VERSION ""

NS_ :

BS_:

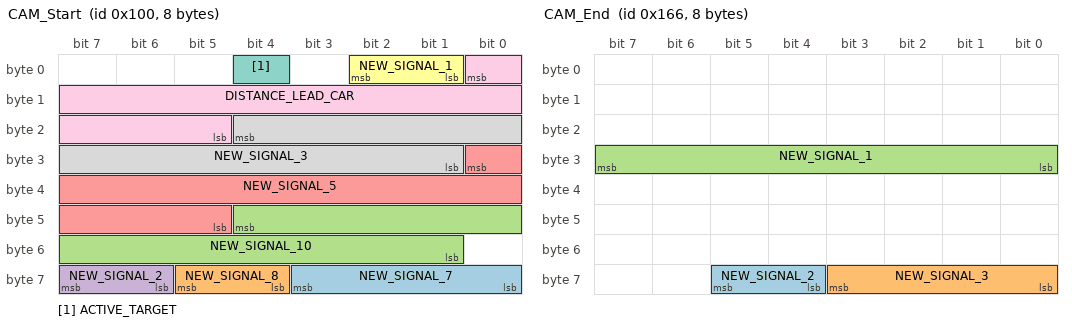
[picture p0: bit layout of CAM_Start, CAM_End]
BO_ 256 CAM_Start: 8 XXX
 SG_ NEW_SIGNAL_7 : 56|4@1+ (1,0) [0|15] "" XXX
 SG_ NEW_SIGNAL_8 : 61|2@0+ (1,0) [0|15] "" XXX
 SG_ NEW_SIGNAL_10 : 44|12@0+ (1,0) [0|15] "" XXX
 SG_ NEW_SIGNAL_2 : 63|2@0+ (1,0) [0|3] "" XXX
 SG_ NEW_SIGNAL_5 : 24|12@0+ (1,0) [0|255] "" XXX
 SG_ NEW_SIGNAL_1 : 2|2@0+ (1,0) [0|1] "" XXX
 SG_ ACTIVE_TARGET : 4|1@0+ (1,0) [0|1] "" XXX
 SG_ NEW_SIGNAL_3 : 20|12@0+ (1,0) [0|7] "" XXX
 SG_ DISTANCE_LEAD_CAR : 0|12@0+ (1,0) [0|255] "" XXX

BO_ 358 CAM_End: 8 XXX
 SG_ NEW_SIGNAL_2 : 61|2@0+ (1,0) [0|3] "" XXX
 SG_ NEW_SIGNAL_3 : 59|4@0+ (1,0) [0|15] "" XXX
 SG_ NEW_SIGNAL_1 : 31|8@0+ (1,0) [0|255] "" XXX

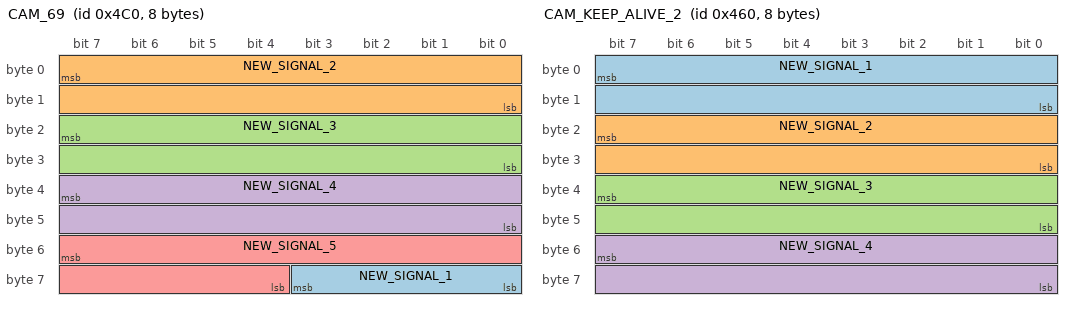
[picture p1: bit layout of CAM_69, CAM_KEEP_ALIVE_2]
BO_ 1216 CAM_69: 8 XXX
 SG_ NEW_SIGNAL_1 : 56|4@1+ (1,0) [0|15] "" XXX
 SG_ NEW_SIGNAL_2 : 7|16@0+ (1,0) [0|65535] "" XXX
 SG_ NEW_SIGNAL_3 : 23|16@0+ (1,0) [0|65535] "" XXX
 SG_ NEW_SIGNAL_4 : 39|16@0+ (1,0) [0|65535] "" XXX
 SG_ NEW_SIGNAL_5 : 55|12@0+ (1,0) [0|7] "" XXX

BO_ 1120 CAM_KEEP_ALIVE_2: 8 XXX
 SG_ NEW_SIGNAL_1 : 7|16@0+ (1,0) [0|65535] "" XXX
 SG_ NEW_SIGNAL_2 : 23|16@0+ (1,0) [0|65535] "" XXX
 SG_ NEW_SIGNAL_3 : 39|16@0+ (1,0) [0|65535] "" XXX
 SG_ NEW_SIGNAL_4 : 55|16@0+ (1,0) [0|65535] "" XXX

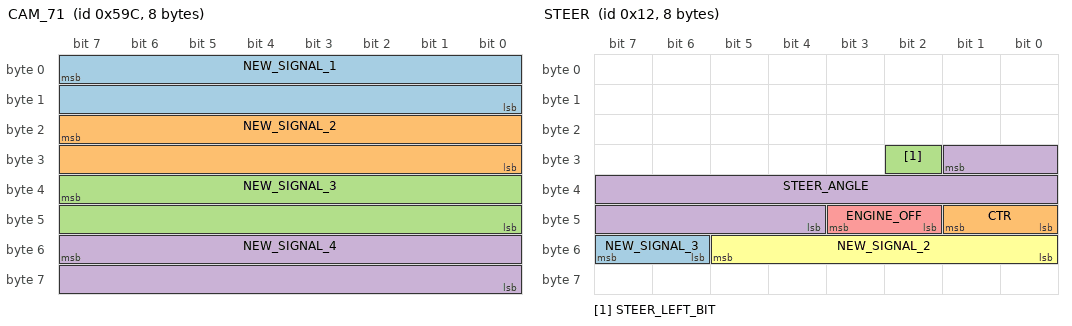
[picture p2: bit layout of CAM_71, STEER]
BO_ 1436 CAM_71: 8 XXX
 SG_ NEW_SIGNAL_1 : 7|16@0+ (1,0) [0|255] "" XXX
 SG_ NEW_SIGNAL_2 : 23|16@0+ (1,0) [0|65535] "" XXX
 SG_ NEW_SIGNAL_3 : 39|16@0+ (1,0) [0|65535] "" XXX
 SG_ NEW_SIGNAL_4 : 55|16@0+ (1,0) [0|65535] "" XXX

BO_ 18 STEER: 8 XXX
 SG_ NEW_SIGNAL_3 : 55|2@0+ (1,0) [0|15] "" XXX
 SG_ CTR : 41|2@0+ (1,0) [0|3] "" XXX
 SG_ STEER_LEFT_BIT : 26|1@0+ (1,0) [0|1] "" XXX
 SG_ STEER_ANGLE : 25|14@0- (1,375) [0|65536] "" XXX
 SG_ ENGINE_OFF : 43|2@0+ (1,0) [0|63] "" XXX
 SG_ NEW_SIGNAL_2 : 53|6@0+ (1,0) [0|15] "" XXX

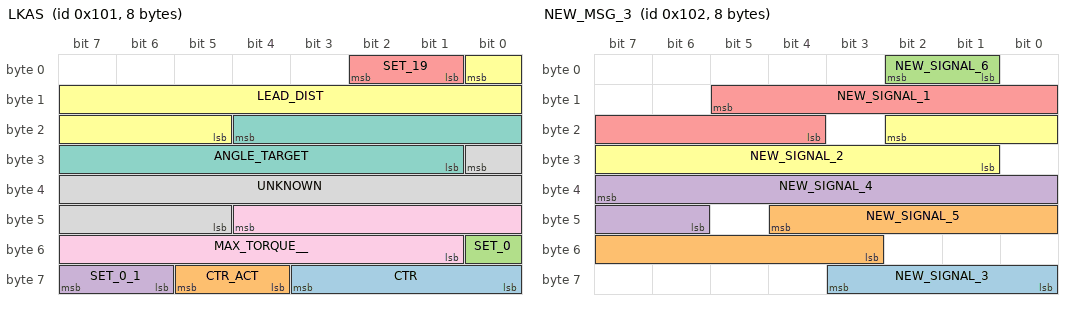
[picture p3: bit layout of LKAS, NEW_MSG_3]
BO_ 257 LKAS: 8 XXX
 SG_ CTR : 59|4@0+ (1,0) [0|255] "" XXX
 SG_ CTR_ACT : 61|2@0+ (1,0) [0|3] "" XXX
 SG_ SET_0 : 48|1@1+ (1,0) [0|3] "" XXX
 SG_ SET_0_1 : 63|2@0+ (1,0) [0|3] "" XXX
 SG_ SET_19 : 2|2@0+ (1,0) [0|255] "" XXX
 SG_ LEAD_DIST : 0|12@0+ (1,0) [0|255] "" XXX
 SG_ ANGLE_TARGET : 20|12@0+ (1,0) [0|4095] "" XXX
 SG_ UNKNOWN : 24|12@0+ (1,0) [0|4095] "" XXX
 SG_ MAX_TORQUE__ : 44|12@0- (1,0) [0|4095] "" XXX

BO_ 258 NEW_MSG_3: 8 XXX
 SG_ NEW_SIGNAL_3 : 59|4@0+ (1,0) [0|255] "" XXX
 SG_ NEW_SIGNAL_5 : 44|10@0- (1,0) [0|1] "" XXX
 SG_ NEW_SIGNAL_6 : 1|2@1+ (1,0) [0|3] "" XXX
 SG_ NEW_SIGNAL_4 : 39|10@0- (1,0) [0|1] "" XXX
 SG_ NEW_SIGNAL_1 : 13|10@0- (1,0) [0|255] "" XXX
 SG_ NEW_SIGNAL_2 : 18|10@0- (1,0) [0|255] "" XXX

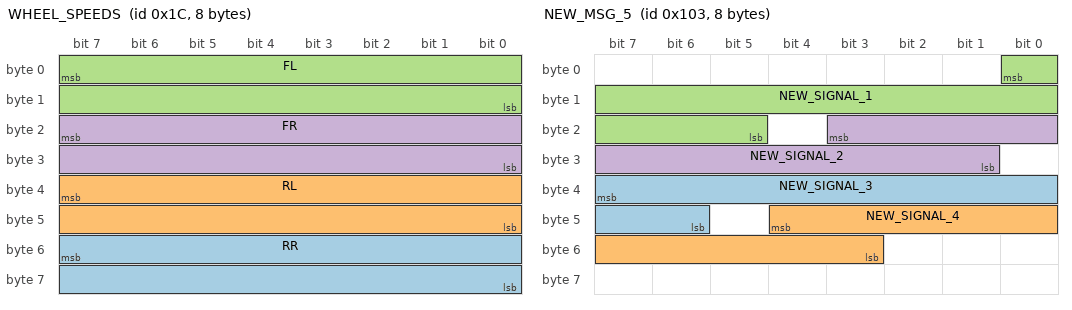
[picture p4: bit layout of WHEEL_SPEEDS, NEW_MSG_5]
BO_ 28 WHEEL_SPEEDS: 8 XXX
 SG_ RR : 55|16@0+ (0.01,-100) [0|65535] "" XXX
 SG_ RL : 39|16@0+ (0.01,-102) [0|65535] "" XXX
 SG_ FL : 7|16@0+ (0.01,-100) [0|65535] "" XXX
 SG_ FR : 23|16@0+ (0.01,-100) [0|65535] "" XXX

BO_ 259 NEW_MSG_5: 8 XXX
 SG_ NEW_SIGNAL_3 : 39|10@0- (1,0) [0|1] "" XXX
 SG_ NEW_SIGNAL_4 : 44|10@0- (1,0) [0|1] "" XXX
 SG_ NEW_SIGNAL_1 : 0|12@0- (1,0) [0|255] "" XXX
 SG_ NEW_SIGNAL_2 : 19|11@0- (1,0) [0|10000000] "" XXX

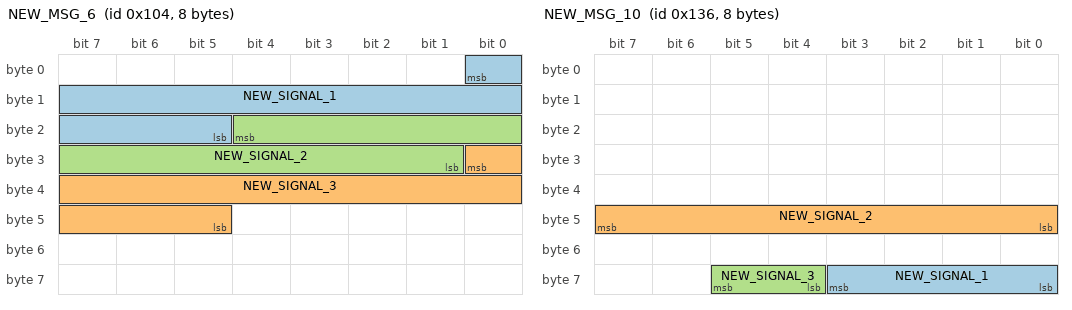
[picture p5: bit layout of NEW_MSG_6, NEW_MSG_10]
BO_ 260 NEW_MSG_6: 8 XXX
 SG_ NEW_SIGNAL_1 : 0|12@0+ (1,0) [0|255] "" XXX
 SG_ NEW_SIGNAL_3 : 24|12@0+ (1,0) [0|1] "" XXX
 SG_ NEW_SIGNAL_2 : 20|12@0- (1,0) [0|1] "" XXX

BO_ 261 NEW_MSG_7: 8 XXX
 SG_ NEW_SIGNAL_1 : 15|8@0+ (1,0) [0|255] "" XXX

BO_ 262 NEW_MSG_8: 8 XXX
 SG_ NEW_SIGNAL_1 : 15|8@0- (1,0) [0|255] "" XXX
 SG_ NEW_SIGNAL_2 : 7|8@0+ (1,0) [0|255] "" XXX

BO_ 263 NEW_MSG_9: 8 XXX
 SG_ NEW_SIGNAL_1 : 15|8@0+ (1,0) [0|255] "" XXX

BO_ 310 NEW_MSG_10: 8 XXX
 SG_ NEW_SIGNAL_1 : 56|4@1+ (1,0) [0|255] "" XXX
 SG_ NEW_SIGNAL_2 : 47|8@0+ (1,0) [0|255] "" XXX
 SG_ NEW_SIGNAL_3 : 61|2@0+ (1,0) [0|3] "" XXX

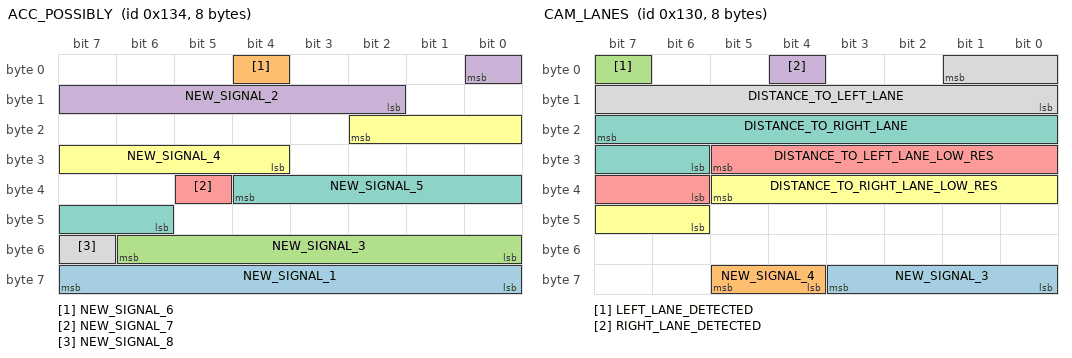
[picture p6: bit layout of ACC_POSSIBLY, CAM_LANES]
BO_ 308 ACC_POSSIBLY: 8 XXX
 SG_ NEW_SIGNAL_1 : 63|8@0+ (1,0) [0|255] "" XXX
 SG_ NEW_SIGNAL_6 : 4|1@0+ (1,0) [0|255] "" XXX
 SG_ NEW_SIGNAL_3 : 54|7@0+ (1,0) [0|15] "" XXX
 SG_ NEW_SIGNAL_2 : 0|7@0+ (1,0) [0|63] "" XXX
 SG_ NEW_SIGNAL_7 : 37|1@0+ (1,0) [0|1] "" XXX
 SG_ NEW_SIGNAL_4 : 18|7@0+ (1,0) [0|15] "" XXX
 SG_ NEW_SIGNAL_5 : 36|7@0+ (1,0) [0|1] "" XXX
 SG_ NEW_SIGNAL_8 : 55|1@0+ (1,0) [0|1] "" XXX

BO_ 304 CAM_LANES: 8 XXX
 SG_ NEW_SIGNAL_3 : 59|4@0+ (1,0) [0|255] "" XXX
 SG_ NEW_SIGNAL_4 : 61|2@0+ (1,0) [0|3] "" XXX
 SG_ LEFT_LANE_DETECTED : 7|1@0+ (1,0) [0|1] "" XXX
 SG_ RIGHT_LANE_DETECTED : 4|1@0+ (1,0) [0|255] "" XXX
 SG_ DISTANCE_TO_LEFT_LANE_LOW_RES : 29|8@0+ (1,0) [0|4095] "" XXX
 SG_ DISTANCE_TO_RIGHT_LANE_LOW_RES : 37|8@0+ (1,0) [0|15] "" XXX
 SG_ DISTANCE_TO_RIGHT_LANE : 23|10@0- (1,0) [0|2047] "" XXX
 SG_ DISTANCE_TO_LEFT_LANE : 1|10@0- (1,0) [0|1] "" XXX

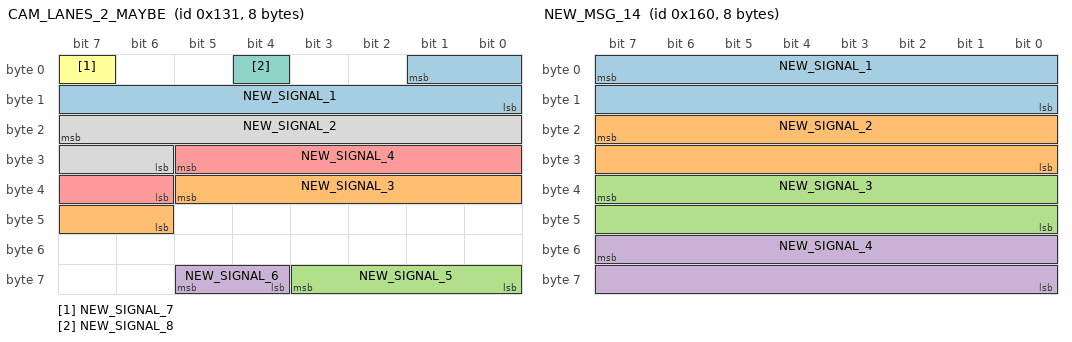
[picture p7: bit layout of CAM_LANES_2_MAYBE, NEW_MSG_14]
BO_ 305 CAM_LANES_2_MAYBE: 8 XXX
 SG_ NEW_SIGNAL_1 : 1|10@0+ (1,0) [0|255] "" XXX
 SG_ NEW_SIGNAL_3 : 37|8@0+ (1,0) [0|15] "" XXX
 SG_ NEW_SIGNAL_5 : 56|4@1+ (1,0) [0|15] "" XXX
 SG_ NEW_SIGNAL_6 : 61|2@0+ (1,0) [0|3] "" XXX
 SG_ NEW_SIGNAL_4 : 29|8@0+ (1,0) [0|1] "" XXX
 SG_ NEW_SIGNAL_7 : 7|1@0+ (1,0) [0|1] "" XXX
 SG_ NEW_SIGNAL_8 : 4|1@0+ (1,0) [0|1] "" XXX
 SG_ NEW_SIGNAL_2 : 23|10@0+ (1,0) [0|4095] "" XXX

BO_ 352 NEW_MSG_14: 8 XXX
 SG_ NEW_SIGNAL_1 : 7|16@0+ (1,0) [0|255] "" XXX
 SG_ NEW_SIGNAL_2 : 23|16@0+ (1,0) [0|65535] "" XXX
 SG_ NEW_SIGNAL_3 : 39|16@0+ (1,0) [0|65535] "" XXX
 SG_ NEW_SIGNAL_4 : 55|16@0+ (1,0) [0|65535] "" XXX

BO_ 355 NEW_MSG_15: 8 XXX
 SG_ NEW_SIGNAL_1 : 7|8@0+ (1,0) [0|127] "" XXX

BO_ 356 NEW_MSG_16: 8 XXX
 SG_ NEW_SIGNAL_1 : 56|4@1+ (1,0) [0|15] "" XXX
 SG_ NEW_SIGNAL_2 : 61|2@0+ (1,0) [0|3] "" XXX

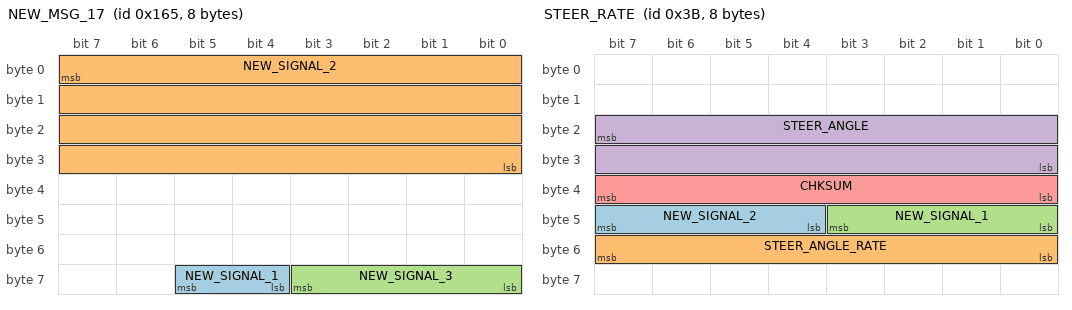
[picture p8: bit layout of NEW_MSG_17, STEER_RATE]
BO_ 357 NEW_MSG_17: 8 XXX
 SG_ NEW_SIGNAL_1 : 61|2@0+ (1,0) [0|3] "" XXX
 SG_ NEW_SIGNAL_2 : 7|32@0+ (1,0) [0|4294967295] "" XXX
 SG_ NEW_SIGNAL_3 : 56|4@1+ (1,0) [0|15] "" XXX

BO_ 59 STEER_RATE: 8 XXX
 SG_ NEW_SIGNAL_2 : 47|4@0+ (1,0) [0|15] "" XXX
 SG_ STEER_ANGLE_RATE : 55|8@0+ (0.05,0) [0|65535] "" XXX
 SG_ NEW_SIGNAL_1 : 43|4@0+ (1,0) [0|15] "" XXX
 SG_ STEER_ANGLE : 23|16@0+ (0.05,-1600) [-500|500] "" XXX
 SG_ CHKSUM : 39|8@0+ (1,0) [0|15] "" XXX

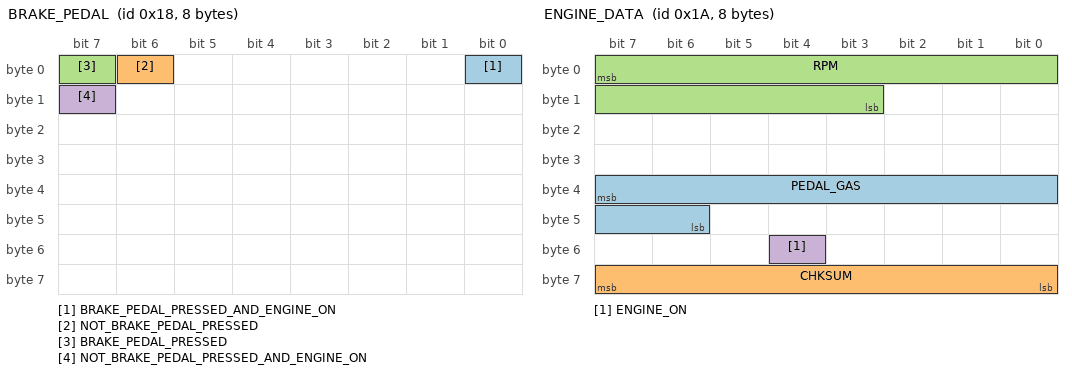
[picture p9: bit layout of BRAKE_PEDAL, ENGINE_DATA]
BO_ 24 BRAKE_PEDAL: 8 XXX
 SG_ BRAKE_PEDAL_PRESSED_AND_ENGINE_ON : 0|1@0+ (1,0) [0|3] "" XXX
 SG_ NOT_BRAKE_PEDAL_PRESSED : 6|1@0+ (1,0) [0|3] "" XXX
 SG_ BRAKE_PEDAL_PRESSED : 7|1@0+ (1,0) [0|65535] "" XXX
 SG_ NOT_BRAKE_PEDAL_PRESSED_AND_ENGINE_ON : 15|1@0+ (1,0) [0|7] "" XXX

BO_ 26 ENGINE_DATA: 8 XXX
 SG_ PEDAL_GAS : 39|10@0+ (1,0) [0|15] "" XXX
 SG_ CHKSUM : 63|8@0- (1,0) [0|15] "" XXX
 SG_ RPM : 7|13@0+ (1,0) [0|15] "" XXX
 SG_ ENGINE_ON : 52|1@0+ (1,0) [0|15] "" XXX

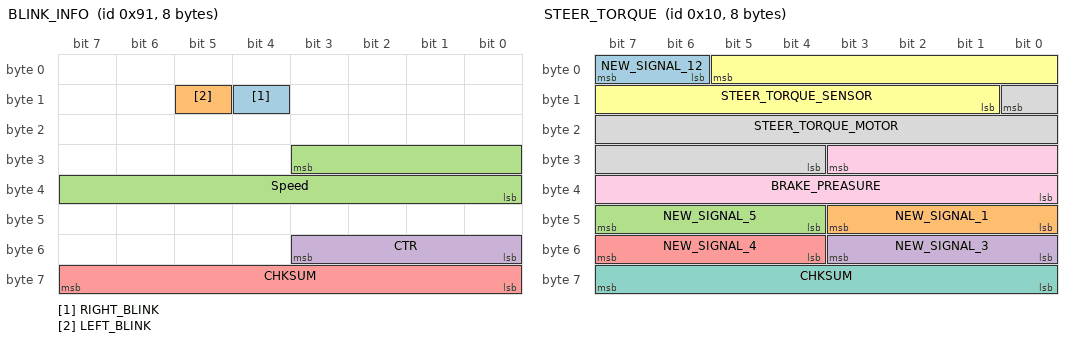
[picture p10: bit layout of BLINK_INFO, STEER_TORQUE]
BO_ 145 BLINK_INFO: 8 XXX
 SG_ RIGHT_BLINK : 12|1@0+ (1,0) [0|3] "" XXX
 SG_ LEFT_BLINK : 13|1@0+ (1,0) [0|3] "" XXX
 SG_ Speed : 27|12@0+ (1,0) [0|255] "" XXX
 SG_ CTR : 51|4@0+ (1,0) [0|15] "" XXX
 SG_ CHKSUM : 63|8@0+ (1,0) [0|15] "" XXX

BO_ 16 STEER_TORQUE: 8 XXX
 SG_ NEW_SIGNAL_12 : 7|2@0+ (1,0) [0|15] "" XXX
 SG_ NEW_SIGNAL_1 : 43|4@0+ (1,0) [0|15] "" XXX
 SG_ NEW_SIGNAL_5 : 47|4@0+ (1,0) [0|15] "" XXX
 SG_ NEW_SIGNAL_3 : 51|4@0+ (1,0) [0|15] "" XXX
 SG_ NEW_SIGNAL_4 : 55|4@0+ (1,0) [0|15] "" XXX
 SG_ STEER_TORQUE_SENSOR : 5|13@0+ (1,-4000) [0|15] "" XXX
 SG_ CHKSUM : 63|8@0- (1,0) [0|15] "" XXX
 SG_ STEER_TORQUE_MOTOR : 8|13@0+ (0.05,-205) [0|15] "" XXX
 SG_ BRAKE_PREASURE : 27|12@0+ (1,0) [0|15] "" XXX

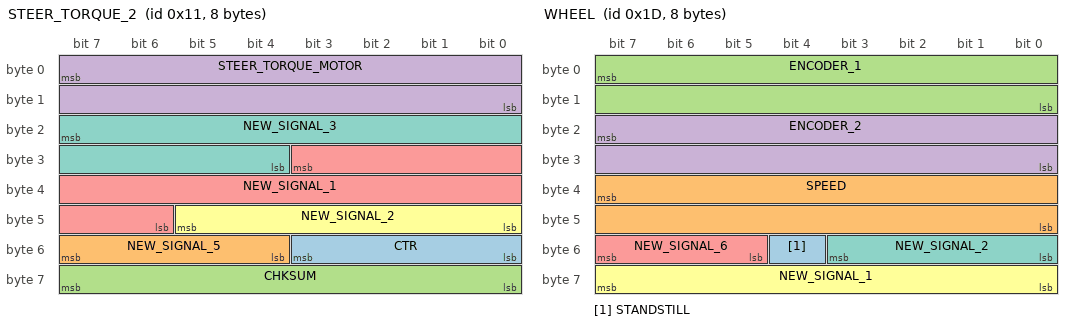
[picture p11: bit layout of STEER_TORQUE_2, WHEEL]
BO_ 17 STEER_TORQUE_2: 8 XXX
 SG_ CTR : 51|4@0+ (1,0) [0|15] "" XXX
 SG_ NEW_SIGNAL_5 : 55|4@0+ (1,0) [0|15] "" XXX
 SG_ CHKSUM : 63|8@0+ (1,0) [0|255] "" XXX
 SG_ STEER_TORQUE_MOTOR : 7|16@0+ (1,0) [0|255] "" XXX
 SG_ NEW_SIGNAL_1 : 27|14@0+ (1,0) [0|255] "" XXX
 SG_ NEW_SIGNAL_2 : 45|6@0+ (1,0) [0|15] "" XXX
 SG_ NEW_SIGNAL_3 : 23|12@0+ (1,0) [0|255] "" XXX

BO_ 29 WHEEL: 8 XXX
 SG_ STANDSTILL : 52|1@0+ (1,0) [0|15] "" XXX
 SG_ SPEED : 39|16@0+ (1,0) [0|127] "" XXX
 SG_ ENCODER_1 : 7|16@0+ (1,0) [0|65535] "" XXX
 SG_ ENCODER_2 : 23|16@0+ (1,0) [0|65535] "" XXX
 SG_ NEW_SIGNAL_6 : 55|3@0+ (1,0) [0|7] "" XXX
 SG_ NEW_SIGNAL_1 : 63|8@0+ (1,0) [0|255] "" XXX
 SG_ NEW_SIGNAL_2 : 51|4@0+ (1,0) [0|15] "" XXX

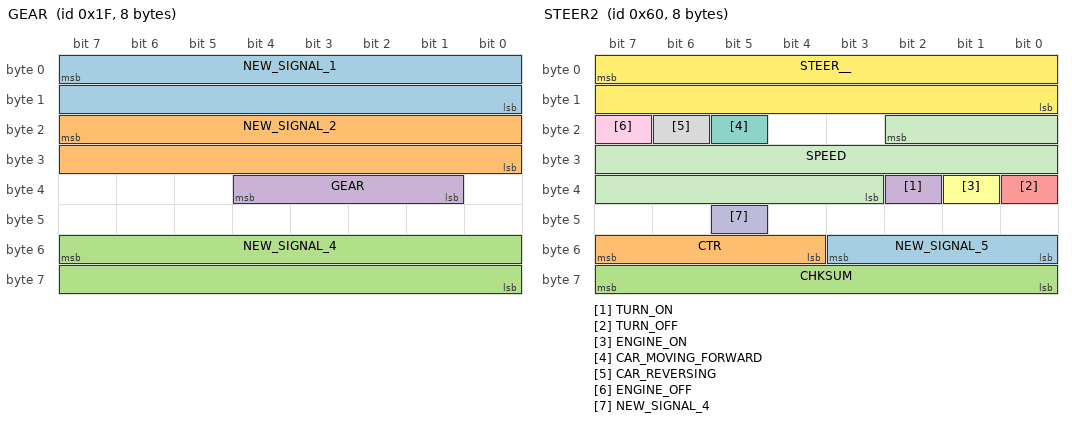
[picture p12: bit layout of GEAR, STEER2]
BO_ 31 GEAR: 8 XXX
 SG_ NEW_SIGNAL_1 : 7|16@0+ (1,0) [0|65535] "" XXX
 SG_ NEW_SIGNAL_2 : 23|16@0+ (1,0) [0|65535] "" XXX
 SG_ NEW_SIGNAL_4 : 55|16@0+ (1,0) [0|65535] "" XXX
 SG_ GEAR : 36|4@0+ (1,0) [0|65535] "" XXX

BO_ 96 STEER2: 8 XXX
 SG_ NEW_SIGNAL_5 : 48|4@1+ (1,0) [0|15] "" XXX
 SG_ CTR : 55|4@0+ (1,0) [0|15] "" XXX
 SG_ CHKSUM : 63|8@0+ (1,0) [0|255] "" XXX
 SG_ TURN_ON : 34|1@0+ (1,0) [0|1] "" XXX
 SG_ TURN_OFF : 32|1@0+ (1,0) [0|1] "" XXX
 SG_ ENGINE_ON : 33|1@0+ (1,0) [0|1] "" XXX
 SG_ CAR_MOVING_FORWARD : 21|1@0+ (1,0) [0|15] "" XXX
 SG_ CAR_REVERSING : 22|1@0+ (1,0) [0|1] "" XXX
 SG_ ENGINE_OFF : 23|1@0+ (1,0) [0|1] "" XXX
 SG_ NEW_SIGNAL_4 : 45|1@0+ (1,0) [0|15] "" XXX
 SG_ SPEED : 18|16@0- (0.00621371,-62.1371) [-65635|65635] "MPH" XXX
 SG_ STEER__ : 7|16@0+ (1,0) [0|65535] "" XXX

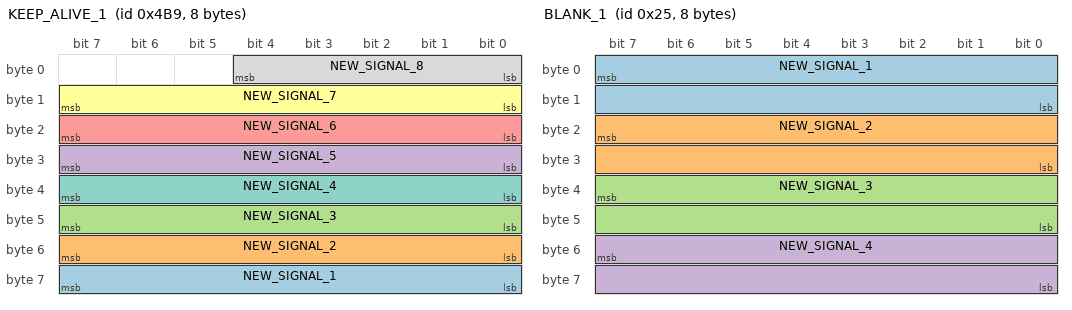
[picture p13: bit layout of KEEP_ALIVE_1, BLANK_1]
BO_ 1209 KEEP_ALIVE_1: 8 XXX
 SG_ NEW_SIGNAL_1 : 63|8@0+ (1,0) [0|255] "" XXX
 SG_ NEW_SIGNAL_2 : 55|8@0+ (1,0) [0|255] "" XXX
 SG_ NEW_SIGNAL_3 : 47|8@0+ (1,0) [0|255] "" XXX
 SG_ NEW_SIGNAL_5 : 31|8@0+ (1,0) [0|255] "" XXX
 SG_ NEW_SIGNAL_6 : 23|8@0+ (1,0) [0|255] "" XXX
 SG_ NEW_SIGNAL_7 : 15|8@0+ (1,0) [0|255] "" XXX
 SG_ NEW_SIGNAL_4 : 39|8@0+ (1,0) [0|255] "" XXX
 SG_ NEW_SIGNAL_8 : 4|5@0+ (1,0) [0|127] "" XXX

BO_ 37 BLANK_1: 8 XXX
 SG_ NEW_SIGNAL_1 : 7|16@0+ (1,0) [0|65535] "" XXX
 SG_ NEW_SIGNAL_2 : 23|16@0+ (1,0) [0|65535] "" XXX
 SG_ NEW_SIGNAL_3 : 39|16@0+ (1,0) [0|65535] "" XXX
 SG_ NEW_SIGNAL_4 : 55|16@0+ (1,0) [0|65535] "" XXX

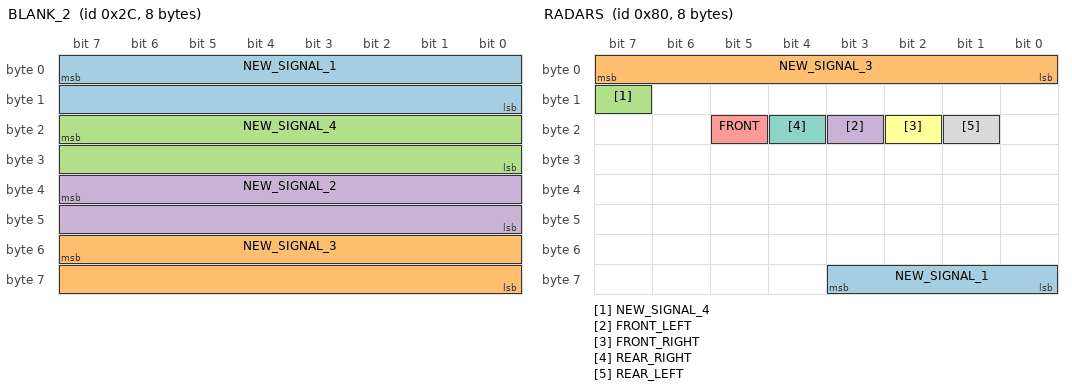
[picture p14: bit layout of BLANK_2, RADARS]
BO_ 44 BLANK_2: 8 XXX
 SG_ NEW_SIGNAL_1 : 7|16@0+ (1,0) [0|16777215] "" XXX
 SG_ NEW_SIGNAL_3 : 55|16@0+ (1,0) [0|65535] "" XXX
 SG_ NEW_SIGNAL_4 : 23|16@0+ (1,0) [0|65535] "" XXX
 SG_ NEW_SIGNAL_2 : 39|16@0+ (1,0) [0|16777215] "" XXX

BO_ 128 RADARS: 8 XXX
 SG_ NEW_SIGNAL_1 : 59|4@0+ (1,0) [0|255] "" XXX
 SG_ NEW_SIGNAL_3 : 7|8@0+ (1,0) [0|255] "" XXX
 SG_ NEW_SIGNAL_4 : 15|1@0+ (1,0) [0|255] "" XXX
 SG_ FRONT_LEFT : 19|1@0+ (1,0) [0|255] "" XXX
 SG_ FRONT : 21|1@0+ (1,0) [0|1] "" XXX
 SG_ FRONT_RIGHT : 18|1@0+ (1,0) [0|1] "" XXX
 SG_ REAR_RIGHT : 20|1@0+ (1,0) [0|15] "" XXX
 SG_ REAR_LEFT : 17|1@0+ (1,0) [0|1] "" XXX

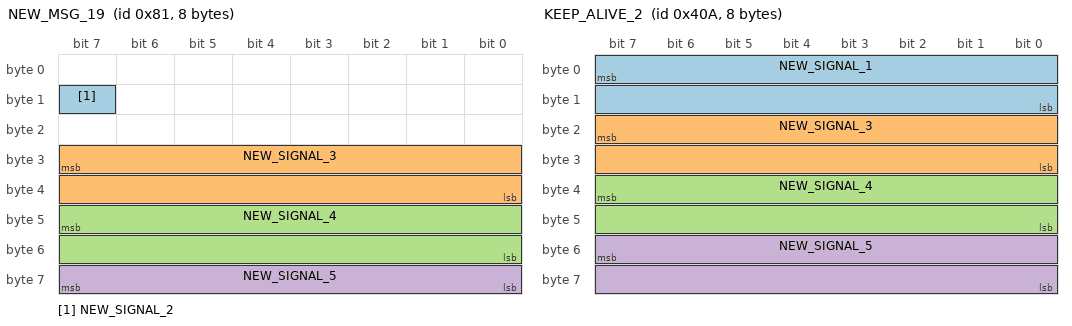
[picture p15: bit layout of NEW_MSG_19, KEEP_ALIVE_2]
BO_ 129 NEW_MSG_19: 8 XXX
 SG_ NEW_SIGNAL_2 : 15|1@0+ (1,0) [0|65535] "" XXX
 SG_ NEW_SIGNAL_3 : 31|16@0+ (1,0) [0|65535] "" XXX
 SG_ NEW_SIGNAL_4 : 47|16@0+ (1,0) [0|65535] "" XXX
 SG_ NEW_SIGNAL_5 : 56|8@1+ (1,0) [0|15] "" XXX

BO_ 1034 KEEP_ALIVE_2: 8 XXX
 SG_ NEW_SIGNAL_1 : 7|16@0+ (1,0) [0|255] "" XXX
 SG_ NEW_SIGNAL_3 : 23|16@0+ (1,0) [0|255] "" XXX
 SG_ NEW_SIGNAL_4 : 39|16@0+ (1,0) [0|255] "" XXX
 SG_ NEW_SIGNAL_5 : 55|16@0+ (1,0) [0|255] "" XXX

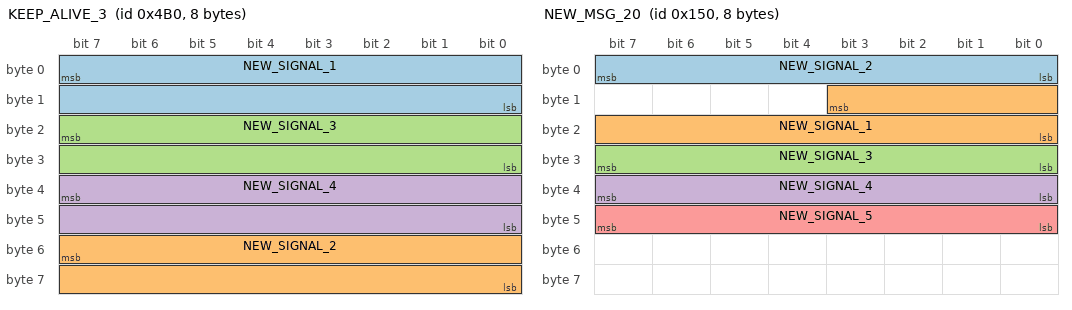
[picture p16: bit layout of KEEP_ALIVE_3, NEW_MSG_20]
BO_ 1200 KEEP_ALIVE_3: 8 XXX
 SG_ NEW_SIGNAL_1 : 7|16@0+ (1,0) [0|255] "" XXX
 SG_ NEW_SIGNAL_2 : 55|16@0+ (1,0) [0|255] "" XXX
 SG_ NEW_SIGNAL_3 : 23|16@0+ (1,0) [0|65535] "" XXX
 SG_ NEW_SIGNAL_4 : 39|16@0+ (1,0) [0|65535] "" XXX

BO_ 354 CAM_KEEP_ALIVE_1: 8 XXX
 SG_ NEW_SIGNAL_1 : 7|16@0+ (1,0) [0|65535] "" XXX
 SG_ NEW_SIGNAL_2 : 23|16@0+ (1,0) [0|65535] "" XXX
 SG_ NEW_SIGNAL_3 : 39|16@0+ (1,0) [0|65535] "" XXX
 SG_ NEW_SIGNAL_4 : 55|30@0+ (1,0) [0|65535] "" XXX

BO_ 336 NEW_MSG_20: 8 XXX
 SG_ NEW_SIGNAL_2 : 7|8@0+ (1,0) [0|4095] "" XXX
 SG_ NEW_SIGNAL_1 : 11|12@0+ (1,0) [0|127] "" XXX
 SG_ NEW_SIGNAL_3 : 31|8@0+ (1,0) [0|255] "" XXX
 SG_ NEW_SIGNAL_4 : 39|8@0+ (1,0) [0|255] "" XXX
 SG_ NEW_SIGNAL_5 : 47|8@0+ (1,0) [0|255] "" XXX

BO_ 342 NEW_MSG_21: 8 XXX
 SG_ NEW_SIGNAL_1 : 56|4@1+ (1,0) [0|15] "" XXX
 SG_ NEW_SIGNAL_2 : 63|4@0+ (1,0) [0|15] "" XXX
 SG_ NEW_SIGNAL_4 : 55|4@0+ (1,0) [0|15] "" XXX
 SG_ NEW_SIGNAL_5 : 39|16@0+ (1,0) [0|15] "" XXX
 SG_ NEW_SIGNAL_3 : 48|4@1+ (1,0) [0|15] "" XXX
 SG_ NEW_SIGNAL_7 : 7|16@0+ (1,0) [0|255] "" XXX
 SG_ NEW_SIGNAL_8 : 23|16@0+ (1,0) [0|65535] "" XXX
 SG_ NEW_SIGNAL_6 : 40|4@1+ (1,0) [0|15] "" XXX

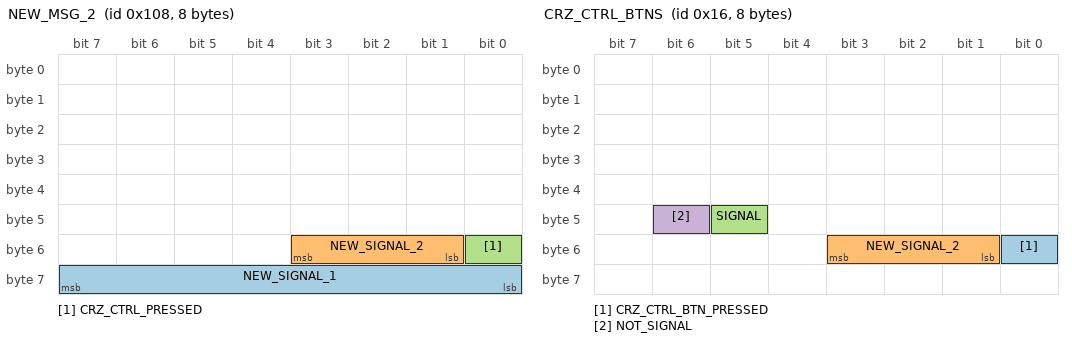
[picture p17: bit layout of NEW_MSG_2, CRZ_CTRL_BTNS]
BO_ 264 NEW_MSG_2: 8 XXX
 SG_ NEW_SIGNAL_1 : 56|8@1+ (1,0) [0|15] "" XXX
 SG_ NEW_SIGNAL_2 : 49|3@1+ (1,0) [0|7] "" XXX
 SG_ CRZ_CTRL_PRESSED : 48|1@0+ (1,0) [0|1] "" XXX

BO_ 22 CRZ_CTRL_BTNS: 8 XXX
 SG_ CRZ_CTRL_BTN_PRESSED : 48|1@0+ (1,0) [0|1] "" XXX
 SG_ NEW_SIGNAL_2 : 51|3@0+ (1,0) [0|7] "" XXX
 SG_ SIGNAL : 45|1@0+ (1,0) [0|15] "" XXX
 SG_ NOT_SIGNAL : 46|1@0+ (1,0) [0|3] "" XXX

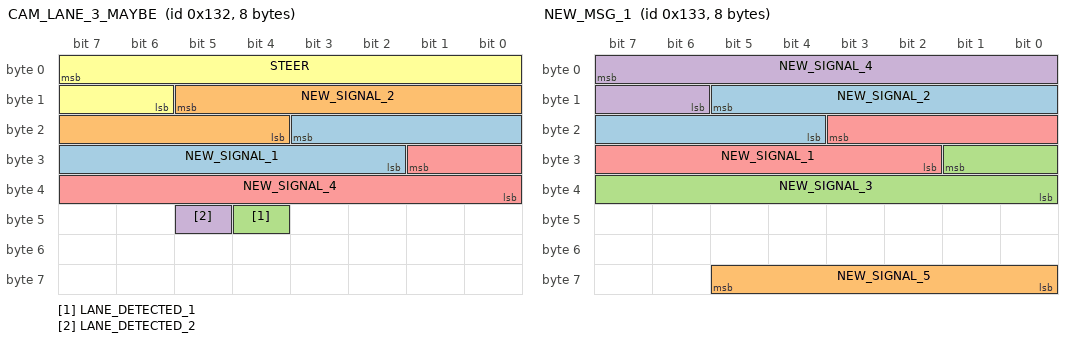
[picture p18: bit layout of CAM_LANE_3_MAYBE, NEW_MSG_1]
BO_ 306 CAM_LANE_3_MAYBE: 8 XXX
 SG_ NEW_SIGNAL_1 : 19|10@0+ (1,0) [0|63] "" XXX
 SG_ NEW_SIGNAL_2 : 13|10@0+ (1,0) [0|255] "" XXX
 SG_ LANE_DETECTED_1 : 44|1@0+ (1,0) [0|1] "" XXX
 SG_ LANE_DETECTED_2 : 45|1@0+ (1,0) [0|1] "" XXX
 SG_ NEW_SIGNAL_4 : 25|10@0+ (1,0) [0|1] "" XXX
 SG_ STEER : 7|10@0+ (1,0) [0|1] "" XXX

BO_ 307 NEW_MSG_1: 8 XXX
 SG_ NEW_SIGNAL_2 : 13|10@0+ (1,0) [0|1] "" XXX
 SG_ NEW_SIGNAL_5 : 61|6@0+ (1,0) [0|1] "" XXX
 SG_ NEW_SIGNAL_3 : 25|10@0+ (1,0) [0|1] "" XXX
 SG_ NEW_SIGNAL_4 : 7|10@0+ (1,0) [0|1] "" XXX
 SG_ NEW_SIGNAL_1 : 19|10@0+ (1,0) [0|1] "" XXX

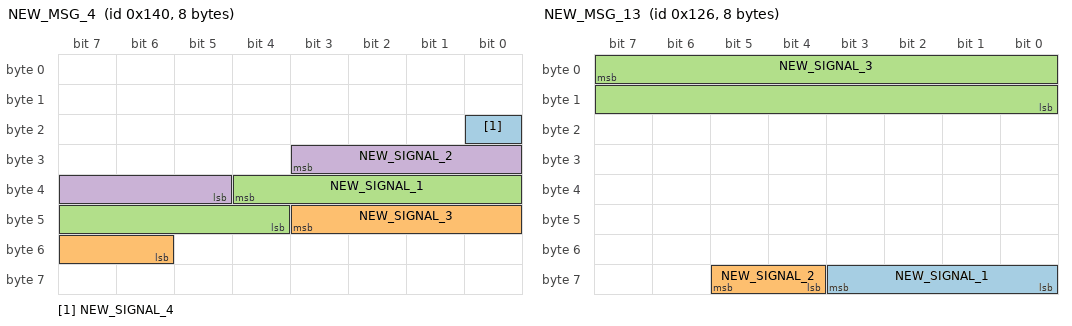
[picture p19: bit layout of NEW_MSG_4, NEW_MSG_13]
BO_ 320 NEW_MSG_4: 8 XXX
 SG_ NEW_SIGNAL_4 : 16|1@0+ (1,0) [0|255] "" XXX
 SG_ NEW_SIGNAL_3 : 43|6@0+ (1,0) [0|1] "" XXX
 SG_ NEW_SIGNAL_1 : 36|9@0+ (1,0) [0|1] "" XXX
 SG_ NEW_SIGNAL_2 : 27|7@0+ (1,0) [0|1] "" XXX

BO_ 321 NEW_MSG_11: 8 XXX
 SG_ NEW_SIGNAL_1 : 5|1@0+ (1,0) [0|1] "" XXX
 SG_ NEW_SIGNAL_2 : 32|1@0+ (1,0) [0|1] "" XXX

BO_ 293 NEW_MSG_12: 8 XXX
 SG_ NEW_SIGNAL_1 : 7|8@0+ (1,0) [0|255] "" XXX
 SG_ NEW_SIGNAL_2 : 39|16@0+ (1,0) [0|255] "" XXX
 SG_ NEW_SIGNAL_3 : 19|4@0+ (1,0) [0|1] "" XXX

BO_ 294 NEW_MSG_13: 8 XXX
 SG_ NEW_SIGNAL_1 : 59|4@0+ (1,0) [0|255] "" XXX
 SG_ NEW_SIGNAL_2 : 61|2@0+ (1,0) [0|1] "" XXX
 SG_ NEW_SIGNAL_3 : 7|16@0+ (1,0) [0|1] "" XXX

BO_ 292 NEW_MSG_18: 8 XXX
 SG_ NEW_SIGNAL_1 : 63|8@0+ (1,0) [0|255] "" XXX

BO_ 291 NEW_MSG_22: 8 XXX
 SG_ NEW_SIGNAL_1 : 39|8@0+ (1,0) [0|255] "" XXX

BO_ 290 NEW_MSG_23: 8 XXX
 SG_ NEW_SIGNAL_1 : 31|5@0+ (1,0) [0|255] "" XXX

BO_ 277 NEW_MSG_24: 8 XXX
 SG_ NEW_SIGNAL_1 : 47|8@0+ (1,0) [0|1] "" XXX

BO_ 278 NEW_MSG_25: 8 XXX

BO_ 273 NEW_MSG_26: 8 XXX
 SG_ NEW_SIGNAL_1 : 23|4@0+ (1,0) [0|3] "" XXX

BO_ 274 NEW_MSG_27: 8 XXX
 SG_ NEW_SIGNAL_1 : 39|8@0+ (1,0) [0|1] "" XXX

BO_ 289 NEW_MSG_28: 8 XXX
 SG_ NEW_SIGNAL_1 : 55|8@0+ (1,0) [0|1] "" XXX

BO_ 20 NEW_MSG_29: 8 XXX
 SG_ RIGHT_BLINK_CLOCK : 23|8@0+ (1,0) [0|1] "" XXX

BO_ 288 NEW_MSG_30: 8 XXX

BU_: RRSRR_FO LRSRR_FO CIPM_FO _DOFIMU2_FO _DOFIMU1_FO DMS_FO AMM_FO EOCM2B_IMX6_FO EOCM2B_K2_FO EOCM2B_K1_FO EOCM2A_IMX6_FO EOCM2A_K2_FO EOCM2A_K1_FO NVS_FO Dummy_FO TestTool_FO LRR_FO RFSRR_FO LFSRR_FO RSRR_FO VIS_FO EOCM_F_FO VIS2_FO
VAL_TABLE_ vt_BooleanValues 1 "true" 0 "false" ;
VAL_TABLE_ FrntVsnInPthVehBrkNwSt 10 "Active" 5 "Inactive" ;
VAL_TABLE_ FrntVsnClostPedBrkNwSt 10 "Active" 5 "Inactive" ;
VAL_TABLE_ DrvrMonSysEngSt 7 "Unused and Reserved 1" 6 "Recovering" 5 "Tracking" 4 "Searching" 3 "Video test port only" 2 "Idle" 1 "Invalid state" 0 "Does not exist or DME" ;
VAL_TABLE_ DrvrMonEngUnrecvrFltCod 7 "Unused and Reserved 3" 6 "Unused and Reserved 2" 5 "Unused and Reserved 1" 4 "Vehicle power supply Errors" 3 "Problem with LED illuminators" 2 "Vehicle input signals Errors" 1 "Problem with imager" 0 "Ok" ;
VAL_TABLE_ DrvrMonEngRecvrFltCod 3 "Engine is unable to find a face" 2 "Input Images too dark" 1 "Input images too bright" 0 "Ok" ;
VAL_TABLE_ DrvrMntrSysVTP 1 "Video test port active" 0 "Video test port inactive" ;
VAL_TABLE_ DrvrAttnStatCnfdc 3 "High" 2 "Medium" 1 "Low" 0 "Lowest" ;
VAL_TABLE_ DrvrAttnStat 7 "Invalid" 6 "Driver is exhibiting sleep" 5 "Driver is exhibiting microsleep" 4 "Attention is Center Console" 3 "Attention is Drivers Lap" 2 "Attention is Off Road" 1 "Attention is On Road" 0 "Unknown" ;
VAL_TABLE_ PPSMd 7 "GNSS and RTX and DR and MM" 6 "DR ONLY" 5 "GNSS and RTX and DR" 4 "GNSS and SBAS and DR" 3 "GNSS and DR" 2 "GNSS and  RTX" 1 "GNSS and SBAS" 0 "GNSS Standalone" ;
VAL_TABLE_ AdvDrvAstMpPrfShrtAcur 3 "Accuracy Is Unknown" 2 "Lowest Accuracy" 1 "Medium Accuracy" 0 "Highest Accuracy" ;
VAL_TABLE_ AdvDrAstMpStbRtOfWay 3 "Not Applicable" 2 "Unknown" 1 "Sub Path Has Right Of Way Over Path" 0 "Path Has Right Of Way Over Sub Path" ;
VAL_TABLE_ AdvDrAstMpStbPrtCalRut 3 "Not Applicable" 2 "Unknown" 1 "Path From This Point On Is Part Of Calculated Route" 0 "Path From This Point On Is Not Part Of Calculated Route" ;
VAL_TABLE_ AdvDrAstMpStbMsgTyp 7 "Unused and Reserved 2" 6 "Metadata" 5 "Profile Long" 4 "Profile Short" 3 "Stub" 2 "Segment" 1 "Position" 0 "Unused and Reserved 1" ;
VAL_TABLE_ AdvDrAstMpStbFmOfWay 15 "Not Applicable" 14 "Pedestrian Zone" 13 "Entrance To Or Exit To Service" 12 "Entrance To Or Exit Of A Car Park" 11 "Service Road Or Frontage Road" 10 "Slip Road per Ramp" 9 "Slip Road per Ramp On A Freeway Or Controlled Access Road" 8 "Parallel Road" 7 "Unused and Reserved 2" 6 "Unused and Reserved 1" 5 "Traffic Square per Special Traffic Figure" 4 "Roundabout Circle" 3 "Single Carriageway" 2 "Multiple Carriageway Or Multiply Digitized Road" 1 "Freeway Or Controlled Access Road That Is Not A Slip Road Or Ramp" 0 "Unknown" ;
VAL_TABLE_ AdvDrAstMpStbCmplxInsct 3 "Not Applicable" 2 "Unknown" 1 "Stub Is Part Of Complex Intersection" 0 "Stub Is Not Part Of Complex Intersection" ;
VAL_TABLE_ AdvDrAstMpSegTunl 3 "Not Applicable" 2 "Unknown" 1 "Segment Is Part Of Tunnel" 0 "Segment Is Not A Part Of Tunnel" ;
VAL_TABLE_ AdvDrAstMpSegPrtCalRut 3 "Not Applicable" 2 "Unknown" 1 "Segment Is Part Of Calculated Route" 0 "Segment Is Not Part Of Calculated Route" ;
VAL_TABLE_ AdvDrAstMpSegMsgTyp 7 "Unused and Reserved 2" 6 "Metadata" 5 "Profile Long" 4 "Profile Short" 3 "Stub" 2 "Segment" 1 "Position" 0 "Unused and Reserved 1" ;
VAL_TABLE_ AdvDrAstMpSegFrmOfWay 15 "Not Applicable" 14 "Pedestrian Zone" 13 "Entrance To Or Exit To Service" 12 "Entrance To Or Exit Of A Car Park" 11 "Service Road Or Frontage Road" 10 "Slip Road per Ramp" 9 "Slip Road per Ramp On A Freeway Or Controlled Access Road" 8 "Parallel Road" 7 "Unused and Reserved 2" 6 "Unused and Reserved 1" 5 "Traffic Square per Special Traffic Figure" 4 "Roundabout Circle" 3 "Single Carriageway" 2 "Multiple Carriageway Or Multiply Digitized Road" 1 "Freeway Or Controlled Access Road That Is Not A Slip Road or Ramp" 0 "Unknown" ;
VAL_TABLE_ AdvDrAstMpSegEffSdLmtTp 7 "Not Applicable" 6 "Explicit Snow" 5 "Explicit Rain" 4 "Explicit Time Of Day" 3 "Explicit By Day" 2 "Explicit By Night" 1 "Explicit On Traffic Sign" 0 "Implicit" ;
VAL_TABLE_ AdvDrAstMpSegDivdRd 3 "Not Applicable" 2 "Unknown" 1 "Segment Is Part Of Divided Road" 0 "Segment Is Not Part Of Divided Road" ;
VAL_TABLE_ AdvDrAstMpSegCmplxInsct 3 "Not Applicable" 2 "Unknown" 1 "Segment Is Part Of Complex Intersection" 0 "Segment Is Not Part Of Complex Intersection" ;
VAL_TABLE_ AdvDrAstMpSegBrdg 3 "Not Applicable" 2 "Unknown" 1 "Segment Is Part Of Bridge" 0 "Segment Not Part Of Bridge" ;
VAL_TABLE_ AdvDrAstMpSegBldUpAra 3 "Not Applicable" 2 "Unknown" 1 "Segment Is Part Of Built Up Area" 0 "Segment Is Not Part Of Built Up Area" ;
VAL_TABLE_ AdvDrAstMpMtdtSpdUnt 1 "Miles Per Hour" 0 "Kilometers Per Hour" ;
VAL_TABLE_ AdvDrAstMpMtdtDrvSd 1 "Driving Side Right" 0 "Driving Side Left" ;
VAL_TABLE_ WSMR_WiFiAssnReq 3 "Unexpected Undefined Connection Behavior" 2 "Wi Fi association failed with available credentials" 1 "Failed to receive Wi Fi credentials after 255 attempts" 0 "SSID and Passphrase Request" ;
VAL_TABLE_ StrgColCommsFlt 2 "Disabled Communications DTC" 1 "No Communications Fault" 0 "Communications Fault" ;
VAL_TABLE_ CPMAPINFO4 1 "Hardware Or Software Error" 0 "No Hardware Or Software Error" ;
VAL_TABLE_ AdvDrvAstMpPrfShrt2Acur 3 "Accuracy Is Unknown" 2 "Lowest Accuracy" 1 "Medium Accuracy" 0 "Highest Accuracy" ;
VAL_TABLE_ InterLghtStat 1 "Interior Lights On" 0 "Interior Light Off" ;
VAL_TABLE_ VehLnStatConf 2 "High Confidence" 1 "Low Confidence" 0 "No Confidence" 3 "Very High Confidence" ;
VAL_TABLE_ VehLnStat 3 "Lane Change To Right" 2 "Lane Change To Left" 1 "Staying in Lane" 0 "Unknown" ;
VAL_TABLE_ HrznPrvdRstRq 1 "Reset Not Required" 0 "Reset Required" ;
VAL_TABLE_ ExptNxtTrnstnDirConf 3 "Very High Confidence" 2 "High Confidence" 1 "Low Confidence" 0 "No Confidence" ;
VAL_TABLE_ ExptNxtTrnstnDir 7 "Reserved4" 6 "Reserved3" 5 "Reserved2" 4 "Reserved1" 3 "Traversing Middle Transition" 2 "Traversing Next Transition Right" 1 "Traversing Next Transition Left" 0 "Unknown" ;
VAL_TABLE_ ADASISMsgTypRetrans 7 "GM System Specific" 6 "Meta Data" 5 "Profile Long" 4 "Profile Short" 3 "Stub" 2 "Segment" 1 "Position" 0 "Checksum" ;
VAL_TABLE_ NVSysStat 7 "Needs Headlights" 6 "Temporarily Unavailable" 5 "Not Dark" 4 "Needs Service" 3 "Active" 2 "Inactive" 1 "Initializing" 0 "Unknown" ;
VAL_TABLE_ NVSysPedWrnIndReq 3 "Unused & Reserved" 2 "Pedestrian Alert" 1 "Pedestrian Detected" 0 "None" ;
VAL_TABLE_ NVSysPedDetCstReq 2 "On" 1 "Off" 0 "No Value" ;
VAL_TABLE_ NVSysPedDetCsCrStVal 2 "On" 1 "Off" 0 "No Value" ;
VAL_TABLE_ FwVsnCinCoutPotT9Rev 2 "Right" 1 "Left" 0 "None" ;
VAL_TABLE_ FwVsnCinCoutPotT8Rev 2 "Right" 1 "Left" 0 "None" ;
VAL_TABLE_ FwVsnCinCoutPotT7Rev 2 "Right" 1 "Left" 0 "None" ;
VAL_TABLE_ FwVsnCinCoutPotT6Rev 2 "Right" 1 "Left" 0 "None" ;
VAL_TABLE_ FwVsnCinCoutPotT5Rev 2 "Right" 1 "Left" 0 "None" ;
VAL_TABLE_ FwVsnCinCoutPotT4Rev 2 "Right" 1 "Left" 0 "None" ;
VAL_TABLE_ FwVsnCinCoutPotT3Rev 2 "Right" 1 "Left" 0 "None" ;
VAL_TABLE_ FwVsnCinCoutPotT2Rev 2 "Right" 1 "Left" 0 "None" ;
VAL_TABLE_ FwVsnCinCoutPotT1Rev 2 "Right" 1 "Left" 0 "None" ;
VAL_TABLE_ FwVsnCinCoutPotT12Rev 2 "Right" 1 "Left" 0 "None" ;
VAL_TABLE_ FwVsnCinCoutPotT11Rev 2 "Right" 1 "Left" 0 "None" ;
VAL_TABLE_ FwVsnCinCoutPotT10Rev 2 "Right" 1 "Left" 0 "None" ;
VAL_TABLE_ GFHBObjDirTrk8 1 "Ahead Traffic" 0 "Incoming Traffic" ;
VAL_TABLE_ GFHBObjDirTrk7 1 "Ahead Traffic" 0 "Incoming Traffic" ;
VAL_TABLE_ GFHBObjDirTrk6 1 "Ahead Traffic" 0 "Incoming Traffic" ;
VAL_TABLE_ GFHBObjDirTrk5 1 "Ahead Traffic" 0 "Incoming Traffic" ;
VAL_TABLE_ GFHBObjDirTrk4 1 "Ahead Traffic" 0 "Incoming Traffic" ;
VAL_TABLE_ GFHBObjDirTrk3 1 "Ahead Traffic" 0 "Incoming Traffic" ;
VAL_TABLE_ GFHBObjDirTrk2 1 "Ahead Traffic" 0 "Incoming Traffic" ;
VAL_TABLE_ GFHBObjDirTrk1 1 "Ahead Traffic" 0 "Incoming Traffic" ;
VAL_TABLE_ GFHBFwVsnRelLaneTrk8 3 "Left Lane" 2 "Right Lane" 1 "Host Lane" 0 "Unknown" ;
VAL_TABLE_ GFHBFwVsnRelLaneTrk7 3 "Left Lane" 2 "Right Lane" 1 "Host Lane" 0 "Unknown" ;
VAL_TABLE_ GFHBFwVsnRelLaneTrk6 3 "Left Lane" 2 "Right Lane" 1 "Host Lane" 0 "Unknown" ;
VAL_TABLE_ GFHBFwVsnRelLaneTrk5 3 "Left Lane" 2 "Right Lane" 1 "Host Lane" 0 "Unknown" ;
VAL_TABLE_ GFHBFwVsnRelLaneTrk4 3 "Left Lane" 2 "Right Lane" 1 "Host Lane" 0 "Unknown" ;
VAL_TABLE_ GFHBFwVsnRelLaneTrk3 3 "Left Lane" 2 "Right Lane" 1 "Host Lane" 0 "Unknown" ;
VAL_TABLE_ GFHBFwVsnRelLaneTrk2 3 "Left Lane" 2 "Right Lane" 1 "Host Lane" 0 "Unknown" ;
VAL_TABLE_ GFHBFwVsnRelLaneTrk1 3 "Left Lane" 2 "Right Lane" 1 "Host Lane" 0 "Unknown" ;
VAL_TABLE_ GFHBFwVsnMesStatTrk8 3 "Measured this cycle" 2 "Latent track not detected this cycle" 1 "New Object" 0 "No Object" ;
VAL_TABLE_ GFHBFwVsnMesStatTrk7 3 "Measured this cycle" 2 "Latent track not detected this cycle" 1 "New Object" 0 "No Object" ;
VAL_TABLE_ GFHBFwVsnMesStatTrk6 3 "Measured this cycle" 2 "Latent track not detected this cycle" 1 "New Object" 0 "No Object" ;
VAL_TABLE_ GFHBFwVsnMesStatTrk5 3 "Measured this cycle" 2 "Latent track not detected this cycle" 1 "New Object" 0 "No Object" ;
VAL_TABLE_ GFHBFwVsnMesStatTrk4 3 "Measured this cycle" 2 "Latent track not detected this cycle" 1 "New Object" 0 "No Object" ;
VAL_TABLE_ GFHBFwVsnMesStatTrk3 3 "Measured this cycle" 2 "Latent track not detected this cycle" 1 "New Object" 0 "No Object" ;
VAL_TABLE_ GFHBFwVsnMesStatTrk2 3 "Measured this cycle" 2 "Latent track not detected this cycle" 1 "New Object" 0 "No Object" ;
VAL_TABLE_ GFHBFwVsnMesStatTrk1 3 "Measured this cycle" 2 "Latent track not detected this cycle" 1 "New Object" 0 "No Object" ;
VAL_TABLE_ GFHBFwVsnCnfdncTrk8 3 "Confident" 2 "Speculative" 1 "Highly Speculative" 0 "Invalid" ;
VAL_TABLE_ GFHBFwVsnCnfdncTrk7 3 "Confident" 2 "Speculative" 1 "Highly Speculative" 0 "Invalid" ;
VAL_TABLE_ GFHBFwVsnCnfdncTrk6 3 "Confident" 2 "Speculative" 1 "Highly Speculative" 0 "Invalid" ;
VAL_TABLE_ GFHBFwVsnCnfdncTrk5 3 "Confident" 2 "Speculative" 1 "Highly Speculative" 0 "Invalid" ;
VAL_TABLE_ GFHBFwVsnCnfdncTrk4 3 "Confident" 2 "Speculative" 1 "Highly Speculative" 0 "Invalid" ;
VAL_TABLE_ GFHBFwVsnCnfdncTrk3 3 "Confident" 2 "Speculative" 1 "Highly Speculative" 0 "Invalid" ;
VAL_TABLE_ GFHBFwVsnCnfdncTrk2 3 "Confident" 2 "Speculative" 1 "Highly Speculative" 0 "Invalid" ;
VAL_TABLE_ GFHBFwVsnCnfdncTrk1 0 "Invalid" 3 "Confident" 2 "Speculative" 1 "Highly Speculative" ;
VAL_TABLE_ GFHBFVsnObjTypTrkRev8 12 "Cluster Object" 11 "Child Close to Danger Zone" 10 "Pedestrian Moving Out of Danger Zone" 9 "Pedestrian Moving Into Danger Zone" 8 "Pedestrian Standing Outside Danger Zone" 7 "No Object Present" 6 "Fixed Roadside Object" 5 "Fixed Overhead Object" 4 "Pedestrian" 3 "Motorcycle/ Bicycle" 2 "Large Vehicle (Semi)" 1 "4 Wheel Vehicle (Car)" 0 "Unknown" ;
VAL_TABLE_ GFHBFVsnObjTypTrkRev7 12 "Cluster Object" 11 "Child Close to Danger Zone" 10 "Pedestrian Moving Out of Danger Zone" 9 "Pedestrian Moving Into Danger Zone" 8 "Pedestrian Standing Outside Danger Zone" 7 "No Object Present" 6 "Fixed Roadside Object" 5 "Fixed Overhead Object" 4 "Pedestrian" 3 "Motorcycle/ Bicycle" 2 "Large Vehicle (Semi)" 1 "4 Wheel Vehicle (Car)" 0 "Unknown" ;
VAL_TABLE_ GFHBFVsnObjTypTrkRev6 12 "Cluster Object" 11 "Child Close to Danger Zone" 10 "Pedestrian Moving Out of Danger Zone" 9 "Pedestrian Moving Into Danger Zone" 8 "Pedestrian Standing Outside Danger Zone" 7 "No Object Present" 6 "Fixed Roadside Object" 5 "Fixed Overhead Object" 4 "Pedestrian" 3 "Motorcycle/ Bicycle" 2 "Large Vehicle (Semi)" 1 "4 Wheel Vehicle (Car)" 0 "Unknown" ;
VAL_TABLE_ GFHBFVsnObjTypTrkRev5 12 "Cluster Object" 11 "Child Close to Danger Zone" 10 "Pedestrian Moving Out of Danger Zone" 9 "Pedestrian Moving Into Danger Zone" 8 "Pedestrian Standing Outside Danger Zone" 7 "No Object Present" 6 "Fixed Roadside Object" 5 "Fixed Overhead Object" 4 "Pedestrian" 3 "Motorcycle/ Bicycle" 2 "Large Vehicle (Semi)" 1 "4 Wheel Vehicle (Car)" 0 "Unknown" ;
VAL_TABLE_ GFHBFVsnObjTypTrkRev4 12 "Cluster Object" 11 "Child Close to Danger Zone" 10 "Pedestrian Moving Out of Danger Zone" 9 "Pedestrian Moving Into Danger Zone" 8 "Pedestrian Standing Outside Danger Zone" 7 "No Object Present" 6 "Fixed Roadside Object" 5 "Fixed Overhead Object" 4 "Pedestrian" 3 "Motorcycle/ Bicycle" 2 "Large Vehicle (Semi)" 1 "4 Wheel Vehicle (Car)" 0 "Unknown" ;
VAL_TABLE_ GFHBFVsnObjTypTrkRev3 12 "Cluster Object" 11 "Child Close to Danger Zone" 10 "Pedestrian Moving Out of Danger Zone" 9 "Pedestrian Moving Into Danger Zone" 8 "Pedestrian Standing Outside Danger Zone" 7 "No Object Present" 6 "Fixed Roadside Object" 5 "Fixed Overhead Object" 4 "Pedestrian" 3 "Motorcycle/ Bicycle" 2 "Large Vehicle (Semi)" 1 "4 Wheel Vehicle (Car)" 0 "Unknown" ;
VAL_TABLE_ GFHBFVsnObjTypTrkRev2 12 "Cluster Object" 11 "Child Close to Danger Zone" 10 "Pedestrian Moving Out of Danger Zone" 9 "Pedestrian Moving Into Danger Zone" 8 "Pedestrian Standing Outside Danger Zone" 7 "No Object Present" 6 "Fixed Roadside Object" 5 "Fixed Overhead Object" 4 "Pedestrian" 3 "Motorcycle/ Bicycle" 2 "Large Vehicle (Semi)" 1 "4 Wheel Vehicle (Car)" 0 "Unknown" ;
VAL_TABLE_ GFHBFVsnObjTypTrkRev1 12 "Cluster Object" 11 "Child Close to Danger Zone" 10 "Pedestrian Moving Out of Danger Zone" 9 "Pedestrian Moving Into Danger Zone" 8 "Pedestrian Standing Outside Danger Zone" 7 "No Object Present" 6 "Fixed Roadside Object" 5 "Fixed Overhead Object" 4 "Pedestrian" 3 "Motorcycle/ Bicycle" 2 "Large Vehicle (Semi)" 1 "4 Wheel Vehicle (Car" 0 "Unknown" ;
VAL_TABLE_ CRL_Cnfdnc 7 "Reserved4" 6 "Reserved3" 5 "Reserved2" 4 "Reserved1" 3 "Best" 2 "Marking Present" 1 "Weak Marking" 0 "No Lane" ;
VAL_TABLE_ CLL_Cnfdnc 7 "Reserved4" 6 "Reserved3" 5 "Reserved2" 4 "Reserved1" 3 "Best" 2 "Marking Present" 1 "Weak Marking" 0 "No Lane" ;
VAL_TABLE_ VBBrkCtrlSt 4 "Release Control" 3 "Hold Vehicle" 2 "Apply Brake" 1 "Decrease Torque" 0 "No Action" ;
VAL_TABLE_ ObstacleType 6 "NO_OBJECT" 5 "OBJ_GUARDRAIL" 4 "OBJ_TUNNEL " 3 "OBJ_TRAFFIC_SIGN" 2 "OBJ_VEHICLE" 1 "OBJ_BRIDGE " 0 "OBJ_UNKNOWN" ;
VAL_TABLE_ VpathMode 2 "Mid Hi Speed" 1 "Low Speed" 0 "Disabled" ;
VAL_TABLE_ LaneChngStatus 2 "Lane Change Right" 1 "Lane Change Left" 0 "Idle" ;
VAL_TABLE_ TravelDirection 3 "Other (excessive side slip)" 2 "reverse / stopped in rvrs gear" 1 "Forward / stopped in frwd gear" 0 "Unknown" ;
VAL_TABLE_ TrueOrFalse 1 "true" 0 "false" ;
VAL_TABLE_ ModeCommand 5 "Sensing with Reduced Power" 4 "Undefined" 3 "Radio Silent" 2 "Sensing" 1 "Not Sensing" 0 "Undefined" ;
VAL_TABLE_ LaneSnsLLnPosValid 1 "Invalid" 0 "Valid" ;
VAL_TABLE_ LnSnsRLnPosValid 1 "Invalid" 0 "Valid" ;
VAL_TABLE_ Elevation 3 "Low " 2 "mid (reserved)" 1 "high " 0 "Unknown" ;
VAL_TABLE_ ModeCommandFdbk 5 "Sensing with reduced power" 4 "Undefined" 3 "Radio Silent" 2 "Sensing" 1 "Not Sensing" 0 "Undefined" ;
VAL_TABLE_ relativeLane 3 "Left Lane" 2 "Right Lane" 1 "Host Lane" 0 "Unknown" ;
VAL_TABLE_ RoadTypeInfo 5 "Constiction Zone Exit" 4 "Construction Zone Entry" 3 "Highway" 2 "Secondary Road" 1 "City" 0 "Unknown" ;
VAL_TABLE_ ObjectLossInfo 2 "elevation conditions" 1 "tight curve" 0 "not lost" ;
VAL_TABLE_ MeasurementStatus 3 "Measured this cycle" 2 "Latent track not detctd this cyc" 1 "New Object" 0 "No Object" ;
VAL_TABLE_ ObjectType 7 "no object present" 6 "fixed roadside object" 5 "fixed overhead object" 4 "pedestrian" 3 "motocycle  / bicycle" 2 "Large vehicle (semi)" 1 "4 Wheel Vehicle (car, small trk)" 0 "Unknown" ;
VAL_TABLE_ Confidence 3 "confident" 2 "speculative" 1 "highly speculative" 0 "invalid" ;
VAL_TABLE_ DynamicProp 4 "Moving in opposite direction" 3 "Moving in same direction as host" 2 "Has moved but currently stopped" 1 "Has never moved" 0 "Unknown" ;
VAL_TABLE_ DrvWndPosSt 6 "Fully Opened" 5 "Open More Than C" 4 "Position C" 3 "Position B" 2 "Position A" 1 "Open Less Than A" 0 "Fully Closed" ;
VAL_TABLE_ VehMovSta 4 "Invalid" 3 "Reverse" 2 "Forward" 1 "Neutral" 0 "Parked" ;
VAL_TABLE_ OtsdAmbtLtLvlStat 2 "Day" 1 "Night" 0 "Unknown" ;
VAL_TABLE_ RtTrnLmpAtv 2 "On with telltale" 1 "On without telltale" 0 "Off" ;
VAL_TABLE_ LftTrnLmpAtv 2 "On with telltale" 1 "On without telltale" 0 "Off" ;
VAL_TABLE_ HdlmpBmSelectStat 2 "High Beams" 1 "Low Beams" 0 "Unknown" ;
VAL_TABLE_ DTCI_DTCFaultType 3 "Type C" 2 "Type B" 1 "Type A" 0 "Not Supported" ;
VAL_TABLE_ TrnsShftLvrPos 13 "Forward Range J" 12 "Forward Range I" 15 "Lever Position Unknown" 11 "Forward Range H" 10 "Forward Range G" 9 "Forward Range F" 8 "Forward Range E" 7 "Forward Range D" 6 "Forward Range C" 5 "Forward Range B" 4 "Forward Range A" 3 "Neutral Range" 2 "Reverse Range" 1 "Park Range" 0 "Between Ranges" ;
VAL_TABLE_ SysPwrMd 3 "Crank Request" 2 "Run" 1 "Accessory" 0 "Off" ;
VAL_TABLE_ ValidityStates 1 "Invalid" 0 "Valid" ;

CM_ "AUTOGENERATED FILE, DO NOT EDIT";

CM_ "hyundai_kia_mando_front_radar.dbc starts here";
